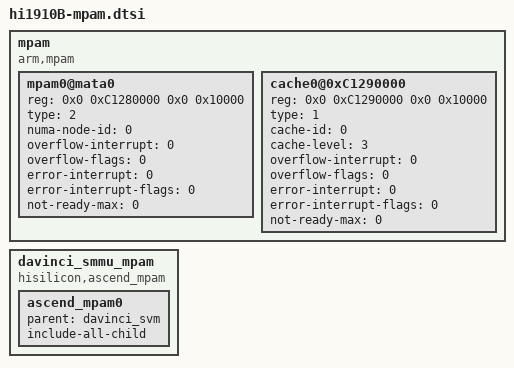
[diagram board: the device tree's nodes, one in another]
	mpam {
		compatible = "arm,mpam";

		mpam0@mata0 {
			reg = <0x0 0xC1280000 0x0 0x10000>;
			type = <2>;
			numa-node-id = <0>;
			overflow-interrupt = <0>;
			overflow-flags = <0>;
			error-interrupt = <0>;
			error-interrupt-flags = <0>;
			not-ready-max = <0>;
		};

		cache0@0xC1290000 {
			reg = <0x0 0xC1290000 0x0 0x10000>;
			type = <1>;
			cache-id = <0>;
			cache-level = <3>;
			overflow-interrupt = <0>;
			overflow-flags = <0>;
			error-interrupt = <0>;
			error-interrupt-flags = <0>;
			not-ready-max = <0>;
		};
	};

	davinci_smmu_mpam {
		compatible = "hisilicon,ascend_mpam";

		ascend_mpam0 {
			parent = "davinci_svm";
			include-all-child;
		};
	};

